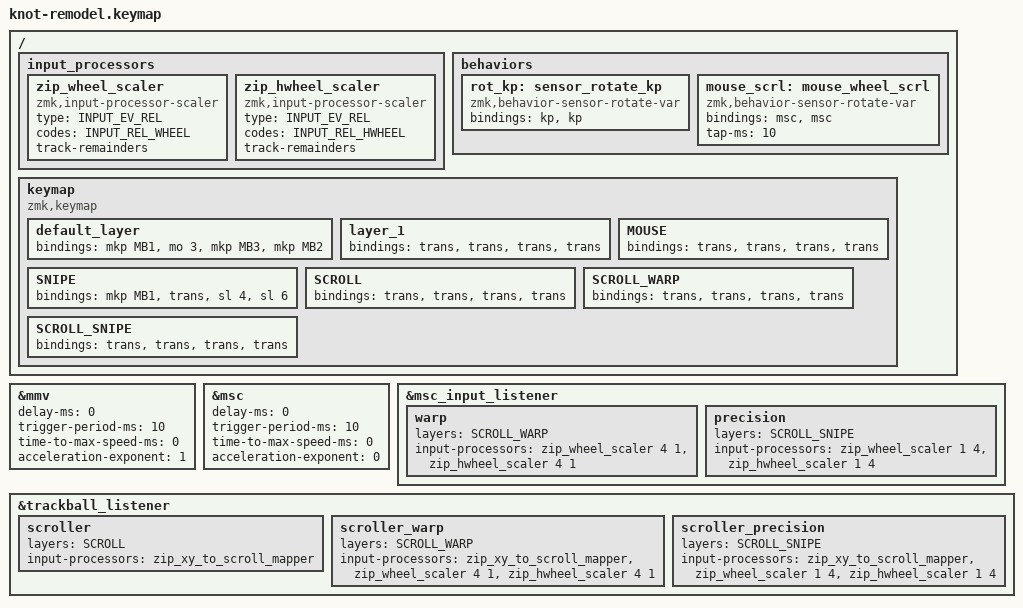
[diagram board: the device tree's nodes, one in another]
#include <physical_layouts.dtsi>
#include <input/processors.dtsi>
#include <zephyr/dt-bindings/input/input-event-codes.h>
#include <behaviors.dtsi>
#include <dt-bindings/zmk/keys.h>
#include <dt-bindings/zmk/pointing.h>

#define NUM 1
#define MOUSE 2
#define SNIPE 3
#define SCROLL 4
#define SCROLL_WARP 5
#define SCROLL_SNIPE 6

&mmv {
    delay-ms = <0>;
    trigger-period-ms = <10>;
    time-to-max-speed-ms = <0>;
    acceleration-exponent = <1>;
};

&msc {
    delay-ms = <0>;
    trigger-period-ms = <10>;
    time-to-max-speed-ms = <0>;
    acceleration-exponent = <0>;
};

/ {
    input_processors {
        zip_wheel_scaler: zip_wheel_scaler {
            compatible = "zmk,input-processor-scaler";
            #input-processor-cells = <2>;
            type = <INPUT_EV_REL>;
            codes = <INPUT_REL_WHEEL>;
            track-remainders;
        };

        zip_hwheel_scaler: zip_hwheel_scaler {
            compatible = "zmk,input-processor-scaler";
            #input-processor-cells = <2>;
            type = <INPUT_EV_REL>;
            codes = <INPUT_REL_HWHEEL>;
            track-remainders;
        };
    };
};

&msc_input_listener {
    warp {
        layers = <SCROLL_WARP>;
        input-processors = <&zip_wheel_scaler 4 1>, <&zip_hwheel_scaler 4 1>;
    };

    precision {
        layers = <SCROLL_SNIPE>;
        input-processors = <&zip_wheel_scaler 1 4>, <&zip_hwheel_scaler 1 4>;
    };
};

&trackball_listener {
    scroller {
        layers = <SCROLL>;
        input-processors = <&zip_xy_to_scroll_mapper>;
    };

    scroller_warp {
        layers = <SCROLL_WARP>;
        input-processors =
            <&zip_xy_to_scroll_mapper>,
            <&zip_wheel_scaler 4 1>,
            <&zip_hwheel_scaler 4 1>;
    };

    scroller_precision {
        layers = <SCROLL_SNIPE>;
        input-processors =
            <&zip_xy_to_scroll_mapper>,
            <&zip_wheel_scaler 1 4>,
            <&zip_hwheel_scaler 1 4>;
    };
};

/ {
    behaviors {
        rot_kp: sensor_rotate_kp {
            compatible = "zmk,behavior-sensor-rotate-var";
            #sensor-binding-cells = <2>;
            bindings = <&kp>, <&kp>;
        };

        mouse_scrl: mouse_wheel_scrl {
            compatible = "zmk,behavior-sensor-rotate-var";
            #sensor-binding-cells = <2>;
            bindings = <&msc>, <&msc>;

            tap-ms = <10>;
        };
    };
};

/ {
    keymap {
        compatible = "zmk,keymap";

        default_layer {
            bindings = <
&mkp MB1  &mo 3  &mkp MB3  &mkp MB2
            >;
        };

        layer_1 {
            bindings = <
&trans  &trans  &trans  &trans
            >;
        };

        MOUSE {
            bindings = <
&trans  &trans  &trans  &trans
            >;
        };

        SNIPE {
            bindings = <
&mkp MB1  &trans  &sl 4  &sl 6
            >;
        };

        SCROLL {
            bindings = <
&trans  &trans  &trans  &trans
            >;
        };

        SCROLL_WARP {
            bindings = <
&trans  &trans  &trans  &trans
            >;
        };

        SCROLL_SNIPE {
            bindings = <
&trans  &trans  &trans  &trans
            >;
        };
    };
};
